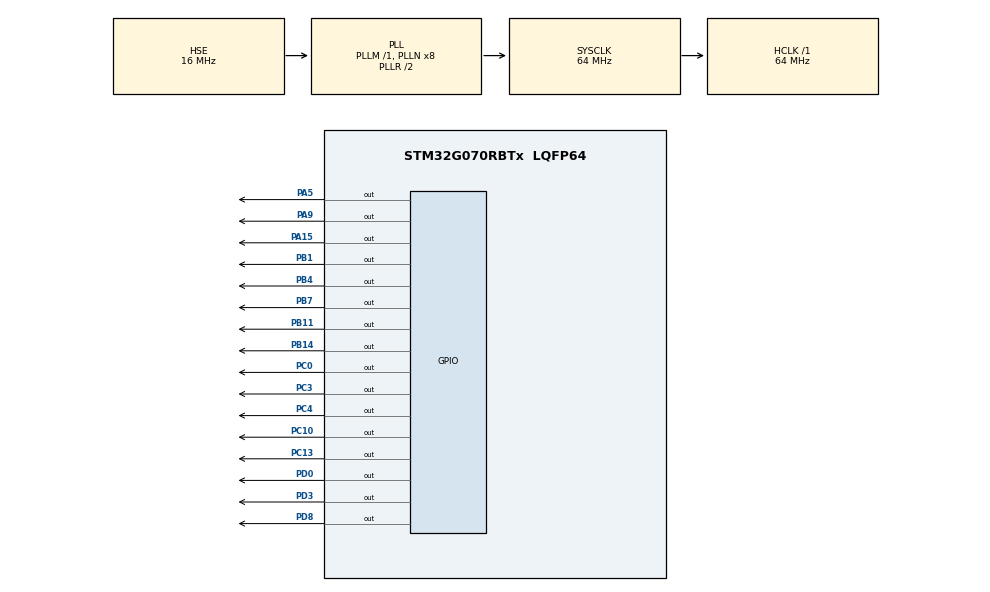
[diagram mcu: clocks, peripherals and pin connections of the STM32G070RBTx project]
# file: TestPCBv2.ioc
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Mcu.Family=STM32G0
Mcu.Name=STM32G070RBTx
Mcu.Package=LQFP64
PA15.Signal=GPIO_Output
PA5.Signal=GPIO_Output
PA9.Signal=GPIO_Output
PB1.Signal=GPIO_Output
PB11.Signal=GPIO_Output
PB14.Signal=GPIO_Output
PB4.Signal=GPIO_Output
PB7.Signal=GPIO_Output
PC0.Signal=GPIO_Output
PC10.Signal=GPIO_Output
PC13.Signal=GPIO_Output
PC3.Signal=GPIO_Output
PC4.Signal=GPIO_Output
PD0.Signal=GPIO_Output
PD3.Signal=GPIO_Output
PD8.Signal=GPIO_Output
PF0-OSC_IN\ (PF0).Mode=HSE-External-Oscillator
PF0-OSC_IN\ (PF0).Signal=RCC_OSC_IN
PF1-OSC_OUT\ (PF1).Mode=HSE-External-Oscillator
PF1-OSC_OUT\ (PF1).Signal=RCC_OSC_OUT
ProjectManager.HeapSize=0x200
ProjectManager.StackSize=0x400
ProjectManager.TargetToolchain=STM32CubeIDE
RCC.ADCFreq_Value=64000000
RCC.AHBFreq_Value=64000000
RCC.CortexFreq_Value=64000000
RCC.EXTERNAL_CLOCK_VALUE=48000
RCC.HCLKFreq_Value=64000000
RCC.HSE_VALUE=16000000
RCC.HSI_VALUE=16000000
RCC.LSE_VALUE=32768
RCC.PLLSourceVirtual=RCC_PLLSOURCE_HSE
RCC.SYSCLKFreq_VALUE=64000000
RCC.SYSCLKSource=RCC_SYSCLKSOURCE_PLLCLK
RCC.VCOOutputFreq_Value=128000000
VP_SYS_VS_DBSignals.Mode=DisableDeadBatterySignals
board=custom

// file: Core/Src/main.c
/* USER CODE BEGIN Header */
/**
  ******************************************************************************
  * @file           : main.c
  * @brief          : Main program body
  ******************************************************************************
  * @attention
  *
  * Copyright (c) 2023 STMicroelectronics.
  * All rights reserved.
  *
  * This software is licensed under terms that can be found in the LICENSE file
  * in the root directory of this software component.
  * If no LICENSE file comes with this software, it is provided AS-IS.
  *
  ******************************************************************************
  */
/* USER CODE END Header */
#include "main.h"

/* USER CODE BEGIN PV */
uint16_t LEDS[16]= {};
/* USER CODE END PV */

void SystemClock_Config(void);
static void MX_GPIO_Init(void);

int main(void)
{

  /* MCU Configuration--------------------------------------------------------*/

  /* Reset of all peripherals, Initializes the Flash interface and the Systick. */
  HAL_Init();

  /* USER CODE BEGIN Init */

  uint8_t i = 1;
  /* USER CODE END Init */

  /* Configure the system clock */
  SystemClock_Config();

  /* Initialize all configured peripherals */
  MX_GPIO_Init();
  /* USER CODE BEGIN 2 */
  LEDs_init();
  /* USER CODE END 2 */

  /* Infinite loop */
  while (1)
  {

    /* USER CODE BEGIN 3 */
	  LEDtoggle(i);
	  i++;
	  if(i > 16)
		  i = 1;
	  HAL_Delay(500);
  }
  /* USER CODE END 3 */
}

void SystemClock_Config(void)
{
  RCC_OscInitTypeDef RCC_OscInitStruct = {0};
  RCC_ClkInitTypeDef RCC_ClkInitStruct = {0};

  /** Configure the main internal regulator output voltage
  */
  HAL_PWREx_ControlVoltageScaling(PWR_REGULATOR_VOLTAGE_SCALE1);

  /** Initializes the RCC Oscillators according to the specified parameters
  * in the RCC_OscInitTypeDef structure.
  */
  RCC_OscInitStruct.OscillatorType = RCC_OSCILLATORTYPE_HSE;
  RCC_OscInitStruct.HSEState = RCC_HSE_ON;
  RCC_OscInitStruct.PLL.PLLState = RCC_PLL_ON;
  RCC_OscInitStruct.PLL.PLLSource = RCC_PLLSOURCE_HSE;
  RCC_OscInitStruct.PLL.PLLM = RCC_PLLM_DIV1;
  RCC_OscInitStruct.PLL.PLLN = 8;
  RCC_OscInitStruct.PLL.PLLP = RCC_PLLP_DIV2;
  RCC_OscInitStruct.PLL.PLLR = RCC_PLLR_DIV2;
  if (HAL_RCC_OscConfig(&RCC_OscInitStruct) != HAL_OK)
  {
    Error_Handler();
  }

  /** Initializes the CPU, AHB and APB buses clocks
  */
  RCC_ClkInitStruct.ClockType = RCC_CLOCKTYPE_HCLK|RCC_CLOCKTYPE_SYSCLK
                              |RCC_CLOCKTYPE_PCLK1;
  RCC_ClkInitStruct.SYSCLKSource = RCC_SYSCLKSOURCE_PLLCLK;
  RCC_ClkInitStruct.AHBCLKDivider = RCC_SYSCLK_DIV1;
  RCC_ClkInitStruct.APB1CLKDivider = RCC_HCLK_DIV1;

  if (HAL_RCC_ClockConfig(&RCC_ClkInitStruct, FLASH_LATENCY_2) != HAL_OK)
  {
    Error_Handler();
  }
}

static void MX_GPIO_Init(void)
{
  GPIO_InitTypeDef GPIO_InitStruct = {0};

  /* GPIO Ports Clock Enable */
  __HAL_RCC_GPIOC_CLK_ENABLE();
  __HAL_RCC_GPIOF_CLK_ENABLE();
  __HAL_RCC_GPIOA_CLK_ENABLE();
  __HAL_RCC_GPIOB_CLK_ENABLE();
  __HAL_RCC_GPIOD_CLK_ENABLE();

  /*Configure GPIO pin Output Level */
  HAL_GPIO_WritePin(GPIOC, GPIO_PIN_13|GPIO_PIN_0|GPIO_PIN_3|GPIO_PIN_4
                          |GPIO_PIN_10, GPIO_PIN_RESET);

  /*Configure GPIO pin Output Level */
  HAL_GPIO_WritePin(GPIOA, GPIO_PIN_5|GPIO_PIN_9|GPIO_PIN_15, GPIO_PIN_RESET);

  /*Configure GPIO pin Output Level */
  HAL_GPIO_WritePin(GPIOB, GPIO_PIN_1|GPIO_PIN_11|GPIO_PIN_14|GPIO_PIN_4
                          |GPIO_PIN_7, GPIO_PIN_RESET);

  /*Configure GPIO pin Output Level */
  HAL_GPIO_WritePin(GPIOD, GPIO_PIN_8|GPIO_PIN_0|GPIO_PIN_3, GPIO_PIN_RESET);

  /*Configure GPIO pins : PC13 PC0 PC3 PC4
                           PC10 */
  GPIO_InitStruct.Pin = GPIO_PIN_13|GPIO_PIN_0|GPIO_PIN_3|GPIO_PIN_4
                          |GPIO_PIN_10;
  GPIO_InitStruct.Mode = GPIO_MODE_OUTPUT_PP;
  GPIO_InitStruct.Pull = GPIO_NOPULL;
  GPIO_InitStruct.Speed = GPIO_SPEED_FREQ_LOW;
  HAL_GPIO_Init(GPIOC, &GPIO_InitStruct);

  /*Configure GPIO pins : PA5 PA9 PA15 */
  GPIO_InitStruct.Pin = GPIO_PIN_5|GPIO_PIN_9|GPIO_PIN_15;
  GPIO_InitStruct.Mode = GPIO_MODE_OUTPUT_PP;
  GPIO_InitStruct.Pull = GPIO_NOPULL;
  GPIO_InitStruct.Speed = GPIO_SPEED_FREQ_LOW;
  HAL_GPIO_Init(GPIOA, &GPIO_InitStruct);

  /*Configure GPIO pins : PB1 PB11 PB14 PB4
                           PB7 */
  GPIO_InitStruct.Pin = GPIO_PIN_1|GPIO_PIN_11|GPIO_PIN_14|GPIO_PIN_4
                          |GPIO_PIN_7;
  GPIO_InitStruct.Mode = GPIO_MODE_OUTPUT_PP;
  GPIO_InitStruct.Pull = GPIO_NOPULL;
  GPIO_InitStruct.Speed = GPIO_SPEED_FREQ_LOW;
  HAL_GPIO_Init(GPIOB, &GPIO_InitStruct);

  /*Configure GPIO pins : PD8 PD0 PD3 */
  GPIO_InitStruct.Pin = GPIO_PIN_8|GPIO_PIN_0|GPIO_PIN_3;
  GPIO_InitStruct.Mode = GPIO_MODE_OUTPUT_PP;
  GPIO_InitStruct.Pull = GPIO_NOPULL;
  GPIO_InitStruct.Speed = GPIO_SPEED_FREQ_LOW;
  HAL_GPIO_Init(GPIOD, &GPIO_InitStruct);

}

void Error_Handler(void)
{
  __disable_irq();
  while (1)
  {
  }
}
